AUTOSAR XML (schema 4-0-3)
package /ComponentTypes
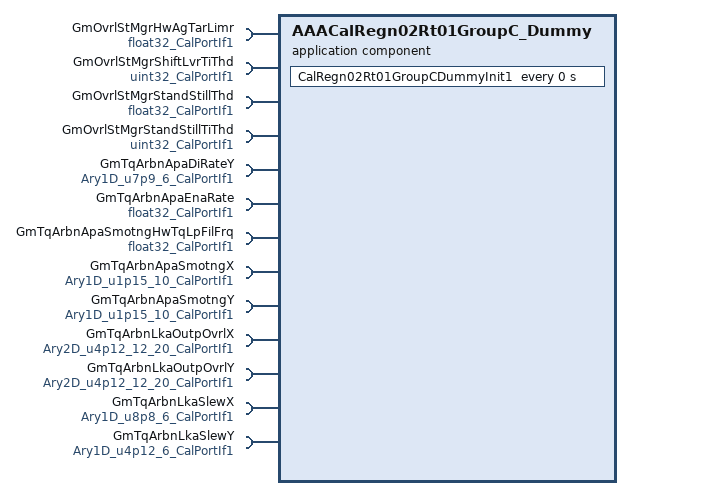
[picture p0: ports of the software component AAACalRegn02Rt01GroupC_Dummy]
  application sw component type AAACalRegn02Rt01GroupC_Dummy
    13 x require port:
      GmOvrlStMgrHwAgTarLimr: parameter-require-com-spec{init-value=30, parameter=Val}, required-interface=float32_CalPortIf1
      GmOvrlStMgrShiftLvrTiThd: parameter-require-com-spec{init-value=200, parameter=Val}, required-interface=uint32_CalPortIf1
      GmOvrlStMgrStandStillThd: parameter-require-com-spec{init-value=2.5, parameter=Val}, required-interface=float32_CalPortIf1
      GmOvrlStMgrStandStillTiThd: parameter-require-com-spec{init-value=250, parameter=Val}, required-interface=uint32_CalPortIf1
      GmTqArbnApaDiRateY: parameter-require-com-spec{init-value=[154, 205, 256, 512, 1024, 2560], parameter=Ary1D}, required-interface=Ary1D_u7p9_6_CalPortIf1
      GmTqArbnApaEnaRate: parameter-require-com-spec{init-value=0.5, parameter=Val}, required-interface=float32_CalPortIf1
      GmTqArbnApaSmotngHwTqLpFilFrq: parameter-require-com-spec{init-value=3, parameter=Val}, required-interface=float32_CalPortIf1
      GmTqArbnApaSmotngX: parameter-require-com-spec{init-value=[0, 3277, 6554, 9830, 13107, 19661, 22938, 26214, 29491, 32768], parameter=Ary1D}, required-interface=Ary1D_u1p15_10_CalPortIf1
      GmTqArbnApaSmotngY: parameter-require-com-spec{init-value=[0, 786, 3113, 6750, 11305, 21463, 26018, 29655, 31982, 32768], parameter=Ary1D}, required-interface=Ary1D_u1p15_10_CalPortIf1
      GmTqArbnLkaOutpOvrlX: parameter-require-com-spec{init-value=12 x [0, 0, 27, 55, 82, 109, 136, 164, 191, 218, 246, 273, 300, 327, 355, 382, 437, 5541, 12628, 16441], parameter=Ary2D}, required-interface=Ary2D_u4p12_12_20_CalPortIf1
      GmTqArbnLkaOutpOvrlY: parameter-require-com-spec{init-value=12 x 20 x 0, parameter=Ary2D}, required-interface=Ary2D_u4p12_12_20_CalPortIf1
      GmTqArbnLkaSlewX: parameter-require-com-spec{init-value=[2560, 10240, 17920, 25600, 33280, 46080], parameter=Ary1D}, required-interface=Ary1D_u8p8_6_CalPortIf1
      GmTqArbnLkaSlewY: parameter-require-com-spec{init-value=6 x 12288, parameter=Ary1D}, required-interface=Ary1D_u4p12_6_CalPortIf1
    behavior AAACalRegn02Rt01GroupC_Dummy_InternalBehavior: supports-multiple-instantiation=true
      timing event AAACalRegn02Rt01GroupC_Dummy_InitEvent: start-on-event=CalRegn02Rt01GroupCDummyInit1, period=0
      runnable CalRegn02Rt01GroupCDummyInit1
  swc implementation AAACalRegn02Rt00GroupC_Dummy_Implementation: behavior=AAACalRegn02Rt01GroupC_Dummy_InternalBehavior
    code-descriptors:
      code Default: artifact-descriptors=autosar-engineering-object={short-label=Default, category=SWSRC}
